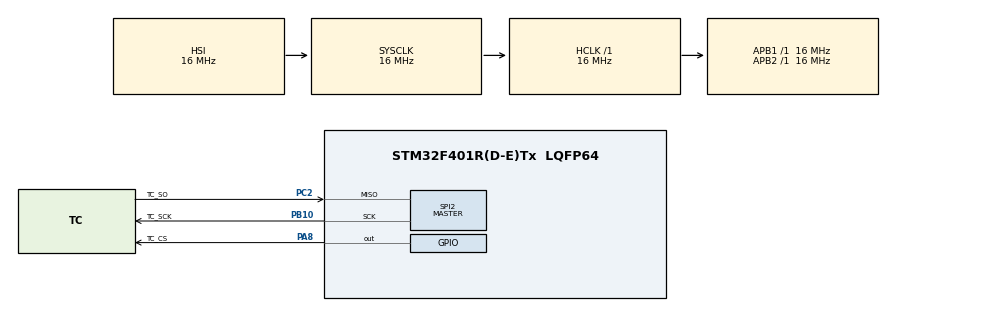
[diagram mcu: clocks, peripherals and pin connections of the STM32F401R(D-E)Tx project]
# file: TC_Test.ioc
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Mcu.Family=STM32F4
Mcu.Name=STM32F401R(D-E)Tx
Mcu.Package=LQFP64
NVIC.PriorityGroup=NVIC_PRIORITYGROUP_4
PA8.GPIO_Label=TC_CS
PA8.PinState=GPIO_PIN_SET
PA8.Signal=GPIO_Output
PB10.GPIO_Label=TC_SCK
PB10.Mode=RX_Only_Simplex_Unidirect_Master
PB10.Signal=SPI2_SCK
PC2.GPIO_Label=TC_SO
PC2.Mode=RX_Only_Simplex_Unidirect_Master
PC2.Signal=SPI2_MISO
ProjectManager.HeapSize=0x200
ProjectManager.StackSize=0x400
ProjectManager.TargetToolchain=STM32CubeIDE
RCC.AHBFreq_Value=16000000
RCC.APB1Freq_Value=16000000
RCC.APB2Freq_Value=16000000
RCC.CortexFreq_Value=16000000
RCC.HSE_VALUE=25000000
RCC.HSI_VALUE=16000000
RCC.LSE_VALUE=32768
RCC.SYSCLKFreq_VALUE=16000000
RCC.VCOOutputFreq_Value=192000000
SPI2.BaudRatePrescaler=SPI_BAUDRATEPRESCALER_256
SPI2.CLKPolarity=SPI_POLARITY_HIGH
SPI2.Direction=SPI_DIRECTION_2LINES_RXONLY
SPI2.Mode=SPI_MODE_MASTER
SPI2.VirtualType=VM_MASTER
board=custom

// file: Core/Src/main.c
/* USER CODE BEGIN Header */
/**
  ******************************************************************************
  * @file           : main.c
  * @brief          : Main program body
  ******************************************************************************
  * @attention
  *
  * Copyright (c) 2026 STMicroelectronics.
  * All rights reserved.
  *
  * This software is licensed under terms that can be found in the LICENSE file
  * in the root directory of this software component.
  * If no LICENSE file comes with this software, it is provided AS-IS.
  *
  ******************************************************************************
  */
/* USER CODE END Header */
#include "main.h"

/* USER CODE BEGIN Includes */
#include <stdio.h>
#include <stdbool.h>
/* USER CODE END Includes */

SPI_HandleTypeDef hspi2;

void SystemClock_Config(void);
static void MX_GPIO_Init(void);
static void MX_SPI2_Init(void);
/* USER CODE BEGIN PFP */
uint8_t MAX6675_ReadRaw(void);
float MAX6675_ReadTempC(void);
/* USER CODE END PFP */

/* USER CODE BEGIN 0 */
uint8_t MAX6675_ReadRaw(void)
{
	uint8_t rx = 0;

	HAL_SPI_Receive(&hspi2, &rx, 1, 100);
	//HAL_GPIO_WritePin(TC_CS_GPIO_Port, TC_CS_Pin, true);

    //uint8_t rx[2] = {0, 0};

    //HAL_GPIO_WritePin(TC_CS_GPIO_Port, TC_CS_Pin, false);
    //HAL_Delay(10);

    //HAL_SPI_Receive(&hspi2, rx, 2, 100);

    //HAL_GPIO_WritePin(TC_CS_GPIO_Port, TC_CS_Pin, true);

    //printf((rx[0] << 8) | rx[1]);
    //return (rx[0] << 8) | rx[1];
	return rx;
}

float MAX6675_ReadTempC(void)
{
	uint16_t raw;
	HAL_GPIO_WritePin(TC_CS_GPIO_Port, TC_CS_Pin, 0);
	HAL_Delay(10);
	raw = MAX6675_ReadRaw();
	raw = raw << 8;
	raw |= MAX6675_ReadRaw();
	HAL_GPIO_WritePin(TC_CS_GPIO_Port, TC_CS_Pin, 1);

	if (raw & 0x4)
	{
		return 0.0f;
	}

	raw = raw >> 3;
	return raw * 0.25f;

    //uint16_t raw = MAX6675_ReadRaw();

    //if (raw & 0x4)
    //    return -1.0f;   // thermocouple open

    //raw >>= 3;

    //return raw * 0.25f;
}

/* USER CODE END 0 */

int main(void)
{

  /* MCU Configuration--------------------------------------------------------*/

  /* Reset of all peripherals, Initializes the Flash interface and the Systick. */
  HAL_Init();

  /* Configure the system clock */
  SystemClock_Config();

  /* Initialize all configured peripherals */
  MX_GPIO_Init();
  MX_SPI2_Init();
  /* USER CODE BEGIN 2 */
  printf("Is this thing on? Hello world!What about now\n");
  /* USER CODE END 2 */

  /* Infinite loop */
  while (1)
  {

    /* USER CODE BEGIN 3 */
	  float tC = MAX6675_ReadTempC();
	  //uint16_t raw = MAX6675_ReadRaw();
	  //printf(tC);
	  //printf("%.6f", tC);
	  //printf("\n");
	  HAL_Delay(250);
  }
  /* USER CODE END 3 */
}

void SystemClock_Config(void)
{
  RCC_OscInitTypeDef RCC_OscInitStruct = {0};
  RCC_ClkInitTypeDef RCC_ClkInitStruct = {0};

  /** Configure the main internal regulator output voltage
  */
  __HAL_RCC_PWR_CLK_ENABLE();
  __HAL_PWR_VOLTAGESCALING_CONFIG(PWR_REGULATOR_VOLTAGE_SCALE2);

  /** Initializes the RCC Oscillators according to the specified parameters
  * in the RCC_OscInitTypeDef structure.
  */
  RCC_OscInitStruct.OscillatorType = RCC_OSCILLATORTYPE_HSI;
  RCC_OscInitStruct.HSIState = RCC_HSI_ON;
  RCC_OscInitStruct.HSICalibrationValue = RCC_HSICALIBRATION_DEFAULT;
  RCC_OscInitStruct.PLL.PLLState = RCC_PLL_NONE;
  if (HAL_RCC_OscConfig(&RCC_OscInitStruct) != HAL_OK)
  {
    Error_Handler();
  }

  /** Initializes the CPU, AHB and APB buses clocks
  */
  RCC_ClkInitStruct.ClockType = RCC_CLOCKTYPE_HCLK|RCC_CLOCKTYPE_SYSCLK
                              |RCC_CLOCKTYPE_PCLK1|RCC_CLOCKTYPE_PCLK2;
  RCC_ClkInitStruct.SYSCLKSource = RCC_SYSCLKSOURCE_HSI;
  RCC_ClkInitStruct.AHBCLKDivider = RCC_SYSCLK_DIV1;
  RCC_ClkInitStruct.APB1CLKDivider = RCC_HCLK_DIV1;
  RCC_ClkInitStruct.APB2CLKDivider = RCC_HCLK_DIV1;

  if (HAL_RCC_ClockConfig(&RCC_ClkInitStruct, FLASH_LATENCY_0) != HAL_OK)
  {
    Error_Handler();
  }
}

static void MX_SPI2_Init(void)
{

  /* SPI2 parameter configuration*/
  hspi2.Instance = SPI2;
  hspi2.Init.Mode = SPI_MODE_MASTER;
  hspi2.Init.Direction = SPI_DIRECTION_2LINES_RXONLY;
  hspi2.Init.DataSize = SPI_DATASIZE_8BIT;
  hspi2.Init.CLKPolarity = SPI_POLARITY_HIGH;
  hspi2.Init.CLKPhase = SPI_PHASE_1EDGE;
  hspi2.Init.NSS = SPI_NSS_SOFT;
  hspi2.Init.BaudRatePrescaler = SPI_BAUDRATEPRESCALER_256;
  hspi2.Init.FirstBit = SPI_FIRSTBIT_MSB;
  hspi2.Init.TIMode = SPI_TIMODE_DISABLE;
  hspi2.Init.CRCCalculation = SPI_CRCCALCULATION_DISABLE;
  hspi2.Init.CRCPolynomial = 10;
  if (HAL_SPI_Init(&hspi2) != HAL_OK)
  {
    Error_Handler();
  }

}

static void MX_GPIO_Init(void)
{
  GPIO_InitTypeDef GPIO_InitStruct = {0};

  /* GPIO Ports Clock Enable */
  __HAL_RCC_GPIOC_CLK_ENABLE();
  __HAL_RCC_GPIOB_CLK_ENABLE();
  __HAL_RCC_GPIOA_CLK_ENABLE();

  /*Configure GPIO pin Output Level */
  HAL_GPIO_WritePin(TC_CS_GPIO_Port, TC_CS_Pin, GPIO_PIN_SET);

  /*Configure GPIO pin : TC_CS_Pin */
  GPIO_InitStruct.Pin = TC_CS_Pin;
  GPIO_InitStruct.Mode = GPIO_MODE_OUTPUT_PP;
  GPIO_InitStruct.Pull = GPIO_NOPULL;
  GPIO_InitStruct.Speed = GPIO_SPEED_FREQ_LOW;
  HAL_GPIO_Init(TC_CS_GPIO_Port, &GPIO_InitStruct);

}

void Error_Handler(void)
{
  __disable_irq();
  while (1)
  {
  }
}
